# M3U6 register map
File version: 2.0.2.11
Registers are 32-bit, read-write, reset 0x0 unless marked. A register's access mark holds for its fields unless they carry their own. Offsets are from the block's base; [hi:lo] are bit positions; {n}, {i} and the like mark numbered series.

## SBI0 — Serial Bus Interface (SBI)
Base 0x40020000
Same registers: SBI1 0x40020020
0x00 CR0 — SBI Control Register 0
  [7] SBIEN
0x04 CR1_A reset 0x9 — SBI Control Register 1 (I2C Mode)
  [7:5] BC, [4] ACK, [2:1] SCK_2_1_, [0] SWRMON ro, [0] SCK_0_ wo
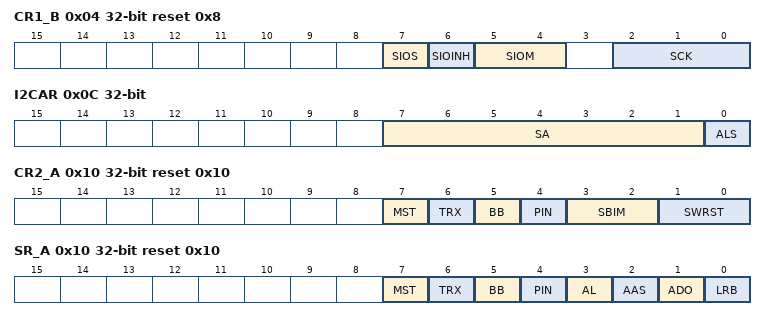
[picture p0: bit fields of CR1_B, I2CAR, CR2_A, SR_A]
0x04 CR1_B reset 0x8 (SBI_CR1 view) — SBI Control Register 1 (SIO Mode)
  [7] SIOS, [6] SIOINH, [5:4] SIOM, [2:0] SCK
0x08 DBR — SBI Data Buffer Register
  [7:0] DB
0x0C I2CAR — SBI I2C Bus Address Register
  [7:1] SA, [0] ALS
0x10 CR2_A wo reset 0x10 — SBI Control Register 2 (I2C Mode)
  [7] MST, [6] TRX, [5] BB, [4] PIN, [3:2] SBIM, [1:0] SWRST
0x10 CR2_B wo reset 0xF3 (SBI_CR2 view) — SBI Control Register 2 (SIO Mode)
  [3:2] SBIM
0x10 SR_A ro reset 0x10 (I2C view) — SBI Status Register (I2C Mode)
  [7] MST, [6] TRX, [5] BB, [4] PIN, [3] AL, [2] AAS, [1] ADO, [0] LRB
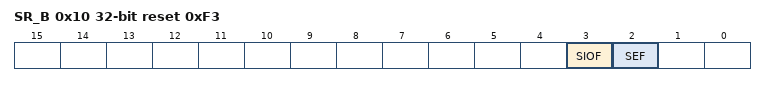
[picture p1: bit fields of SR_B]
0x10 SR_B ro reset 0xF3 (SBI_SR view) — SBI Status Register (SIO Mode)
  [3] SIOF, [2] SEF
0x14 BR0 reset 0xBE — SBI Baud Rate Register 0
  [6] I2SBI

## SC0 — Serial Channel (SC)
Base 0x40020080
Same registers: SC1 0x400200C0, SC2 0x40020100, SC3 0x40020140, SC4 0x40020180
0x00 EN — SC Enable Register
  [0] SIOE
0x04 BUF — SC Buffer Register
  [7:0] TB_RB
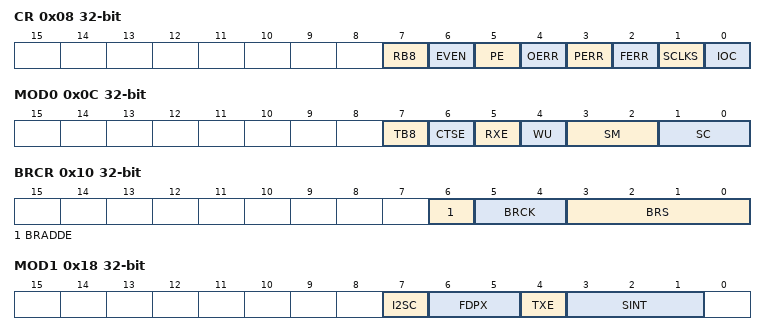
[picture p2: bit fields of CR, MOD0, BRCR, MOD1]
0x08 CR — SC Control Register
  [7] RB8 ro, [6] EVEN, [5] PE, [4] OERR ro, [3] PERR ro, [2] FERR ro, [1] SCLKS, [0] IOC
0x0C MOD0 — SC Mode Control Register 0
  [7] TB8, [6] CTSE, [5] RXE, [4] WU, [3:2] SM, [1:0] SC
0x10 BRCR — SC Baud Rate Generator Control Register
  [6] BRADDE, [5:4] BRCK, [3:0] BRS
0x14 BRADD — SC Baud Rate Generator Control Register 2
  [3:0] BRK
0x18 MOD1 — SC Mode Control Register 1
  [7] I2SC, [6:5] FDPX, [4] TXE, [3:1] SINT
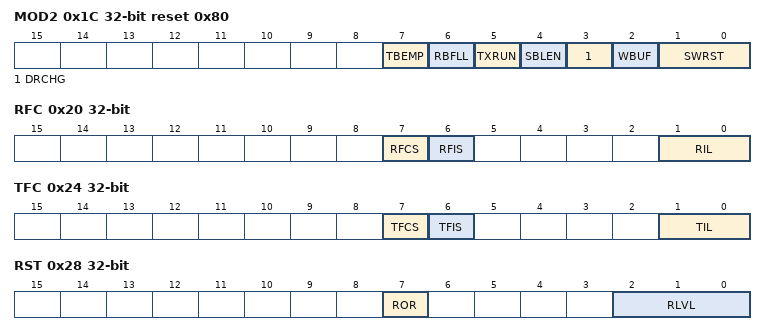
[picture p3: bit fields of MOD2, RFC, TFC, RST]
0x1C MOD2 reset 0x80 — SC Mode Control Register 2
  [7] TBEMP ro, [6] RBFLL ro, [5] TXRUN ro, [4] SBLEN, [3] DRCHG, [2] WBUF, [1:0] SWRST
0x20 RFC — SC RX FIFO Configuration Register
  [7] RFCS wo, [6] RFIS, [1:0] RIL
0x24 TFC — SC TX FIFO Configuration Register
  [7] TFCS wo, [6] TFIS, [1:0] TIL
0x28 RST ro — SC RX FIFO Status Register
  [7] ROR, [2:0] RLVL
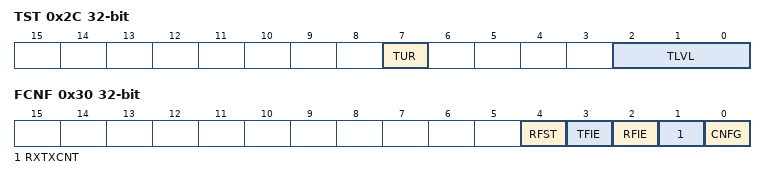
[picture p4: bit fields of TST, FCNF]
0x2C TST ro — SC TX FIFO Status Register
  [7] TUR, [2:0] TLVL
0x30 FCNF — SC FIFO Configuration Register
  [4] RFST, [3] TFIE, [2] RFIE, [1] RXTXCNT, [0] CNFG

## AD — Analog-to-Digital Converter (AD)
Base 0x40030000
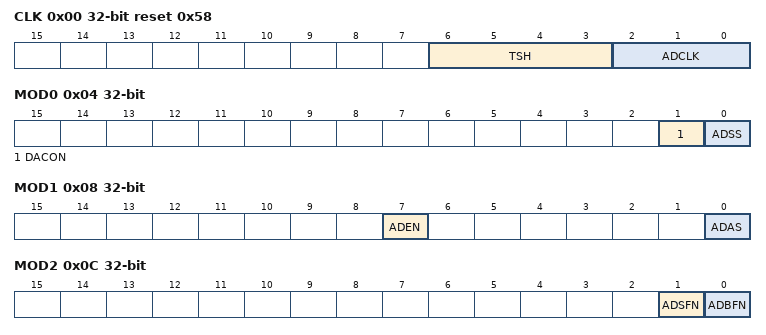
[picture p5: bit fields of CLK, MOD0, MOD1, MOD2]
0x00 CLK reset 0x58 — AD Conversion Clock Setting Register
  [6:3] TSH, [2:0] ADCLK
0x04 MOD0 — AD Mode Control Register 0
  [1] DACON, [0] ADSS wo
0x08 MOD1 — AD Mode Control Register 1
  [7] ADEN, [0] ADAS
0x0C MOD2 ro — AD Mode Control Register 2
  [1] ADSFN, [0] ADBFN
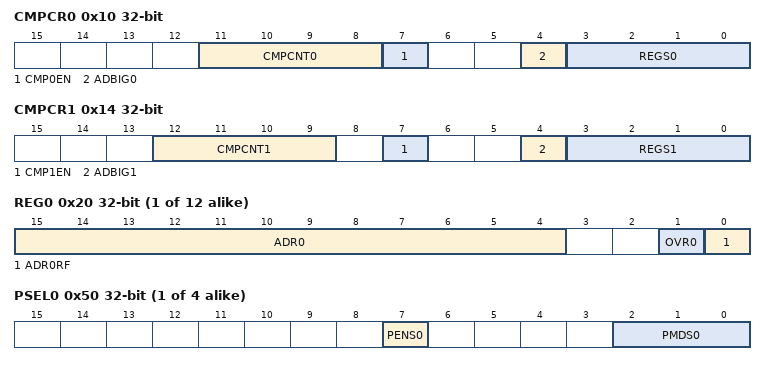
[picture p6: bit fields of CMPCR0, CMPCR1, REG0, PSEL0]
0x10 CMPCR0 — AD Monitoring Setting Register 0
  [11:8] CMPCNT0, [7] CMP0EN, [4] ADBIG0, [3:0] REGS0
0x14 CMPCR1 — AD Monitoring Setting Register 1
  [12:9] CMPCNT1, [7] CMP1EN, [4] ADBIG1, [3:0] REGS1
0x18 CMP0 — AD Conversion Result Comparison Register 0
  [15:4] AD0CMP
0x1C CMP1 — AD Conversion Result Comparison Register 1
  [15:4] AD1CMP
{0x20+4i} REG{i} ro (i=0..11) — AD Conversion Result Register {i:02}
  [15:4] ADR{i}, [1] OVR{i}, [0] ADR{i}RF
{0x50+4i} PSEL{i} (i=0..3) — PMD Trigger Program Number Select Register {i}
  [7] PENS{i}, [2:0] PMDS{i}
{0x80+4i} PINTS{i} (i=0..5) — PMD Trigger Interrupt Select Register {i}
  [1:0] INTSEL{i}
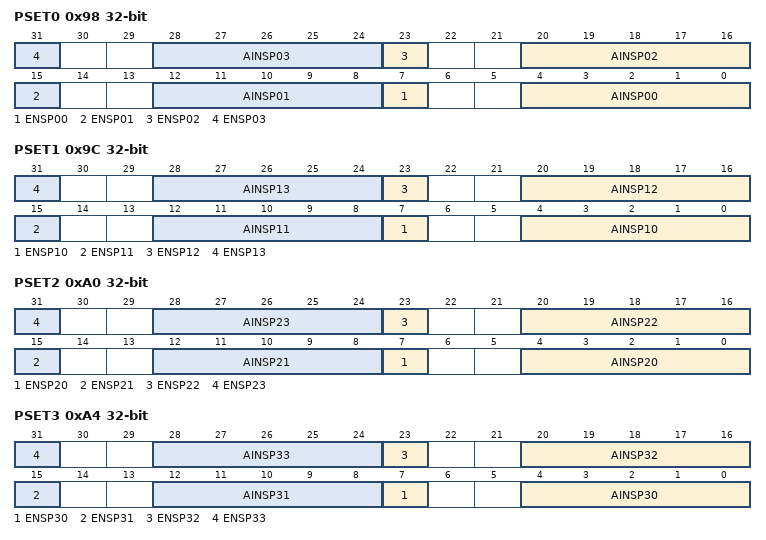
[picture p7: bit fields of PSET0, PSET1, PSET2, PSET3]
0x98 PSET0 — PMD Trigger Program Setting Register 0
  [8n+7] ENSP{n:02} (n=0..3), [8n+4:8n] AINSP{n:02} (n=0..3)
0x9C PSET1 — PMD Trigger Program Setting Register 1
  [8n-73] ENSP{n} (n=10..13), [8n-76:8n-80] AINSP{n} (n=10..13)
0xA0 PSET2 — PMD Trigger Program Setting Register 2
  [8n-153] ENSP{n} (n=20..23), [8n-156:8n-160] AINSP{n} (n=20..23)
0xA4 PSET3 — PMD Trigger Program Setting Register 3
  [8n-233] ENSP{n} (n=30..33), [8n-236:8n-240] AINSP{n} (n=30..33)
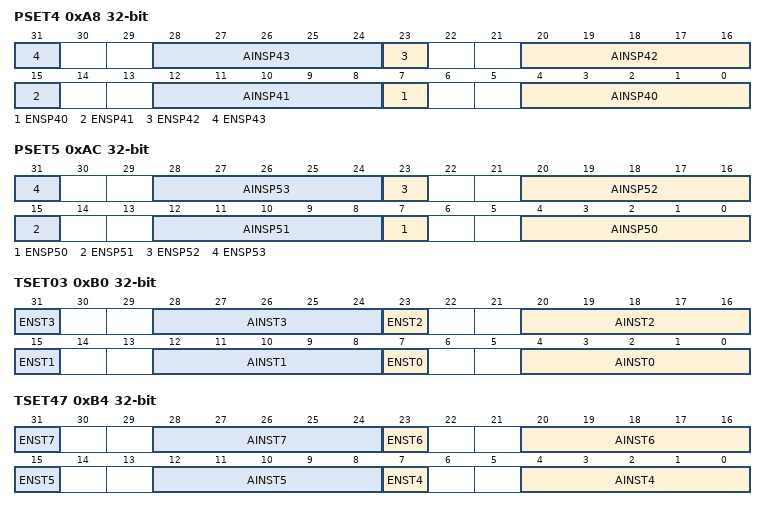
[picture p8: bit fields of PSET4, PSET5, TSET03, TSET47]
0xA8 PSET4 — PMD Trigger Program Setting Register 4
  [8n-313] ENSP{n} (n=40..43), [8n-316:8n-320] AINSP{n} (n=40..43)
0xAC PSET5 — PMD Trigger Program Setting Register 5
  [8n-393] ENSP{n} (n=50..53), [8n-396:8n-400] AINSP{n} (n=50..53)
0xB0 TSET03 — Timer Trigger Program Register 03
  [8n+7] ENST{n} (n=0..3), [8n+4:8n] AINST{n} (n=0..3)
0xB4 TSET47 — Timer Trigger Program Register 47
  [8n-25] ENST{n} (n=4..7), [8n-28:8n-32] AINST{n} (n=4..7)
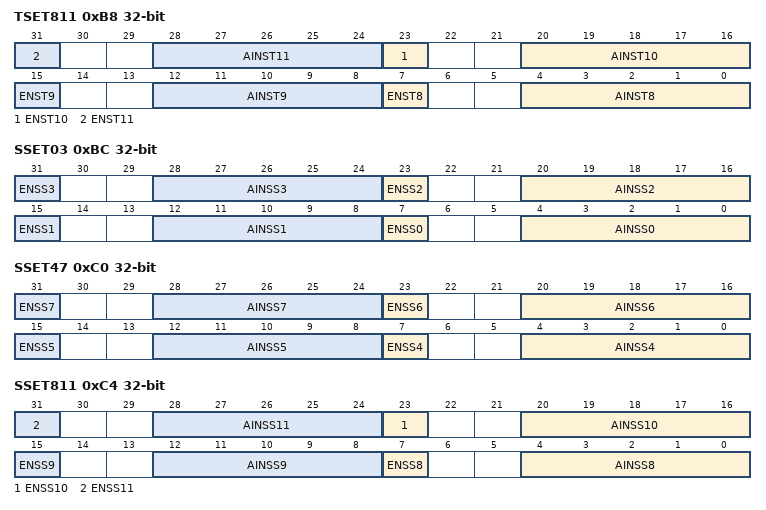
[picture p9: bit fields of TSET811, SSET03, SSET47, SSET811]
0xB8 TSET811 — Timer Trigger Program Register 811
  [8n-57] ENST{n} (n=8..11), [8n-60:8n-64] AINST{n} (n=8..11)
0xBC SSET03 — Software Trigger Program Register 03
  [8n+7] ENSS{n} (n=0..3), [8n+4:8n] AINSS{n} (n=0..3)
0xC0 SSET47 — Software Trigger Program Register 47
  [8n-25] ENSS{n} (n=4..7), [8n-28:8n-32] AINSS{n} (n=4..7)
0xC4 SSET811 — Software Trigger Program Register 811
  [8n-57] ENSS{n} (n=8..11), [8n-60:8n-64] AINSS{n} (n=8..11)
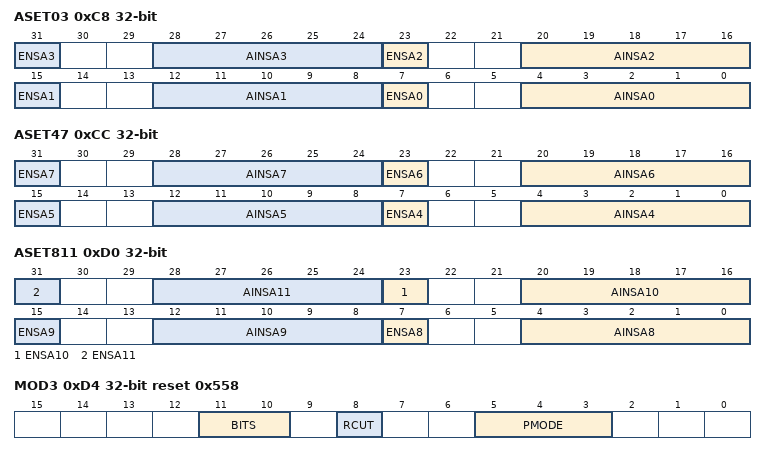
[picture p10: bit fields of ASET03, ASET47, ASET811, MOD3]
0xC8 ASET03 — Constant Conversion Program Register 03
  [8n+7] ENSA{n} (n=0..3), [8n+4:8n] AINSA{n} (n=0..3)
0xCC ASET47 — Constant Conversion Program Register 47
  [8n-25] ENSA{n} (n=4..7), [8n-28:8n-32] AINSA{n} (n=4..7)
0xD0 ASET811 — Constant Conversion Program Register 811
  [8n-57] ENSA{n} (n=8..11), [8n-60:8n-64] AINSA{n} (n=8..11)
0xD4 MOD3 reset 0x558 — AD Mode Control Register 3
  [11:10] BITS, [8] RCUT, [5:3] PMODE
